# K1921VG1T register map
Vendor: NIIET; Series: K1921VGx; File version: 2.8
CPU: other r0p1, little endian, MPU, FPU, 4 interrupt priority bits
Registers are 32-bit, read-write, reset 0x0 unless marked. A register's access mark holds for its fields unless they carry their own. Offsets are from the block's base; [hi:lo] are bit positions.

## USBCTR0 — USB common registers
Base 0x41080800
Same registers: USBCTR1 0x41090800
0x00 HOSTEN — USB Host Enable register
  [0] HOSTEN — Congifure USB output as a host
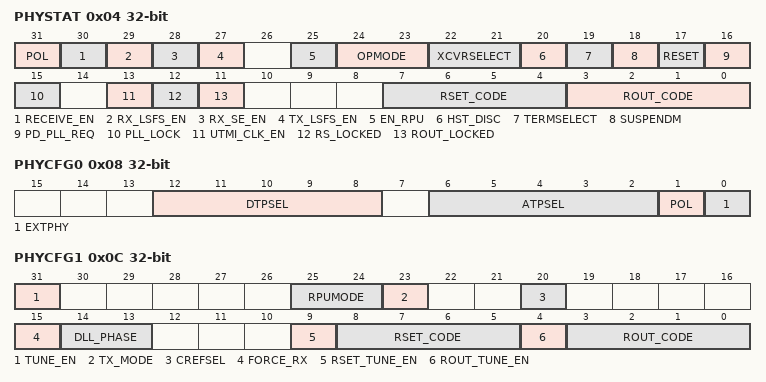
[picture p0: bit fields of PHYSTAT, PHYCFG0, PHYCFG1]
0x04 PHYSTAT ro — USB PHY Layer Status register
  [31] POL — Polarity
  [30] RECEIVE_EN — Receiver status in digital part of phy
  [29] RX_LSFS_EN — RX_LSFS_EN signal status
  [28] RX_SE_EN — RX_SE_EN signal status
  [27] TX_LSFS_EN — TX_LSFS_EN signal status
  [25] EN_RPU — EN_RPU signal status
  [24:23] OPMODE — OPMODE bus status
  [22:21] XCVRSELECT — XCVRSELECT bus status
  [20] HST_DISC — HOST_DISCONNECT signal status
  [19] TERMSELECT — TERMSELECT signal status
  [18] SUSPENDM — SUSPENDM signal status
  [17] RESET — RESET signal status
  [16] PD_PLL_REQ — PD_PLL_REQ signal status
  [15] PLL_LOCK — PLL_LOCK signal status
  [13] UTMI_CLK_EN — Clock out signal present on UTMI interface
  [12] RS_LOCKED — RSOURCE_LOCKED output status
  [11] ROUT_LOCKED — ROUT_LOCKED output status
  [7:4] RSET_CODE — CREF_RSOURCE_CODE - setting resistor tune code value
  [3:0] ROUT_CODE — TX_ROUT_CODE - transmitter output resistor tune code value
0x08 PHYCFG0 — USB Physical Layer Config 0 register
  [12:8] DTPSEL — DTP select
    0=OFF (Internal analog mux is power off); 1=ODT_COMP_OUT (dtp connects to comparator output in calibration block); 2=ODT_EN (dtp connects to calibration block enable signal); 3=RX_SE_DP (dtp connects to DP output of the receiver); 4=RX_SE_DM (dtp connects to DM output of the receiver); 5=RX_LSFS_SDATA (dtp connects to diff output of the receiver); 6=CREF_EN (dtp connects to enable signal of bias current source); 7=EN_RPU (dtp connect RPU resistor); 8=EN_RPU_LOW (dtp connect RPU resistor); 9=TX_SDATA (dtp connects to transmitter data); 10=TX_LSFS_EN (dtp connects to enable transmitter signal); 11=TX_LSFS_OEB (dtp connects to output enable signal of the transmitter); 12=TX_LSFS_SE0 (dtp connects to SE0); 13=RX_SE_EN (dtp connects to enable receiver signal); 14=RX_LSFS_EN (dtp connects to receiver enable signal); 15=EBUF_VALID (dtp connects to compensation buffer ready signal); 16=EBUF_ERROR (dtp connects to compensation buffer error signal); 17=SYNC (dtp connects to SYNC pattern detector); 18=EOP (dtp connects to EOP pattern detector); 19=RESET (dtp connects to reset signal); 20=PLLLOCK (dtp connects to pll lock signal); 21=RXACTIVE (dtp connects to RXActive signal); 22=RXERROR (dtp connects tp RXError signal)
  [6:2] ATPSEL — ATP select
    0=OFF (Internal analog mux is power off); 1=COMP_VR (atp_0 connects to ground and atp_1 connects to comp_vr from calibration block); 2=COMP_VREF (atp_0 connects to ground and atp_1 connects to comp_vref from calibration block); 7=VDDH (atp_0 connects to ground and atp_1 connects to VDDH)
  [1] POL — Polarity
  [0] EXTPHY — Use external PHY Layer
0x0C PHYCFG1 — USB Physical Layer Config 1 register
  [31] TUNE_EN — Tune enable
  [25:24] RPUMODE — RPU compensation mode
    0=DEFAULT (Default value); 2=LOW (TX_RPU_COMP_EN always 0); 3=HIGH (TX_RPU_COMP_EN always 1)
  [23] TX_MODE — Transmitter mode
  [20] CREFSEL — Select type of bsae current
  [15] FORCE_RX — Debug signal: do not shut off receiver when the packet has come
  [14:13] DLL_PHASE — Capture point in bit interval
    0=PERCENT_80 (80% of bit interval); 1=PERCENT_40 (40% of bit interval); 2=PERCENT_60 (60% of bit interval); 3=PERCENT_100 (100% of bit interval)
  [9] RSET_TUNE_EN — Automatic calibration of resistor in current source
  [8:5] RSET_CODE — Setting resistor tune code
  [4] ROUT_TUNE_EN — Automatic transmitter output resistor calibration
  [3:0] ROUT_CODE — Transmitter output resistor tune code
